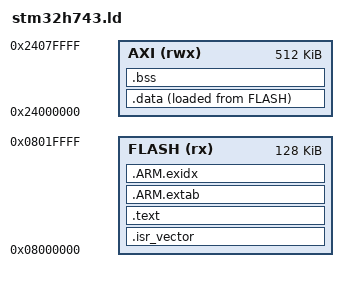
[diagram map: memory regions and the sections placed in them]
ENTRY(Reset_Handler)
MEMORY { FLASH (rx) : ORIGIN = 0x08000000, LENGTH = 128K
 AXI (rwx) : ORIGIN = 0x24000000, LENGTH = 512K }
_estack = ORIGIN(AXI) + LENGTH(AXI);
SECTIONS {
 .isr_vector : { KEEP(*(.isr_vector)) } > FLASH
 .text : { *(.text*) *(.rodata*) . = ALIGN(4); } > FLASH
 .ARM.extab : { *(.ARM.extab*) } > FLASH
 .ARM.exidx : { __exidx_start = .; *(.ARM.exidx*) __exidx_end = .; } > FLASH
 _sidata = LOADADDR(.data);
 .data : { . = ALIGN(4); _sdata = .; *(.data*) . = ALIGN(4); _edata = .; } > AXI AT> FLASH
 .bss : { . = ALIGN(8); _sbss = .; *(.bss*) *(COMMON) . = ALIGN(8); _ebss = .; } > AXI
 _end = .; PROVIDE(end = .);
 ASSERT(_ebss <= _estack - 4096,"AXI overflow")
}
